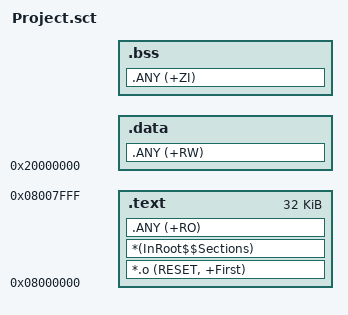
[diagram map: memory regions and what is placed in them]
; *************************************************************
; *** Scatter-Loading Description File generated by uVision ***
; *************************************************************

LR_IROM1 0x08000000 0x00008000  {    ; load region size_region
  .text 0x08000000 0x00008000  {  ; load address = execution address
   *.o (RESET, +First)
   *(InRoot$$Sections)
   .ANY (+RO)
  }
}
LR_IRAM1 +0 0x00004000 {
  .data 0x20000000 {  ; RW data
   .ANY (+RW)
  }
  .bss +0 {
   .ANY (+ZI)
  }
}
